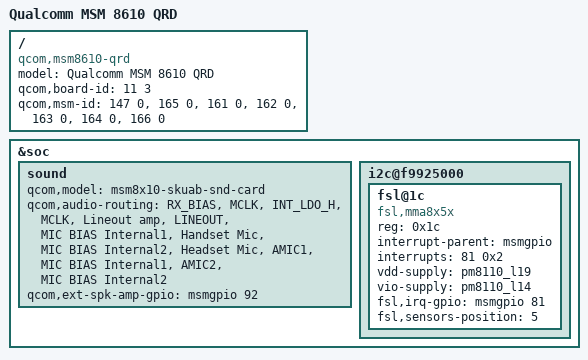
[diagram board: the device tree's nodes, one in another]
/* Copyright (c) 2013, The Linux Foundation. All rights reserved.
 *
 * This program is free software; you can redistribute it and/or modify
 * it under the terms of the GNU General Public License version 2 and
 * only version 2 as published by the Free Software Foundation.
 *
 * This program is distributed in the hope that it will be useful,
 * but WITHOUT ANY WARRANTY; without even the implied warranty of
 * MERCHANTABILITY or FITNESS FOR A PARTICULAR PURPOSE.  See the
 * GNU General Public License for more details.
 */

/dts-v1/;

/include/ "msm8610-qrd.dtsi"

/ {
	model = "Qualcomm MSM 8610 QRD";
	compatible = "qcom,msm8610-qrd", "qcom,msm8610", "qcom,qrd";
	qcom,board-id = <11 3>;
	qcom,msm-id = <147 0>, <165 0>, <161 0>, <162 0>,
				  <163 0>, <164 0>, <166 0>;
};

&soc {
    sound {
        qcom,model = "msm8x10-skuab-snd-card";

        qcom,audio-routing =
            "RX_BIAS", "MCLK",
            "INT_LDO_H", "MCLK",
            "Lineout amp", "LINEOUT",
            "MIC BIAS Internal1", "Handset Mic",
            "MIC BIAS Internal2", "Headset Mic",
            "AMIC1", "MIC BIAS Internal1",
            "AMIC2", "MIC BIAS Internal2";

        qcom,ext-spk-amp-gpio = <&msmgpio 92 0x0>;
    };
    i2c@f9925000 {
		fsl@1c {
			compatible = "fsl,mma8x5x";
			reg = <0x1c>;
			interrupt-parent = <&msmgpio>;
			interrupts = <81 0x2>;
			vdd-supply = <&pm8110_l19>;
			vio-supply = <&pm8110_l14>;
			fsl,irq-gpio = <&msmgpio 81 0x00>;
			fsl,sensors-position = <5>;
		};
	};
};
